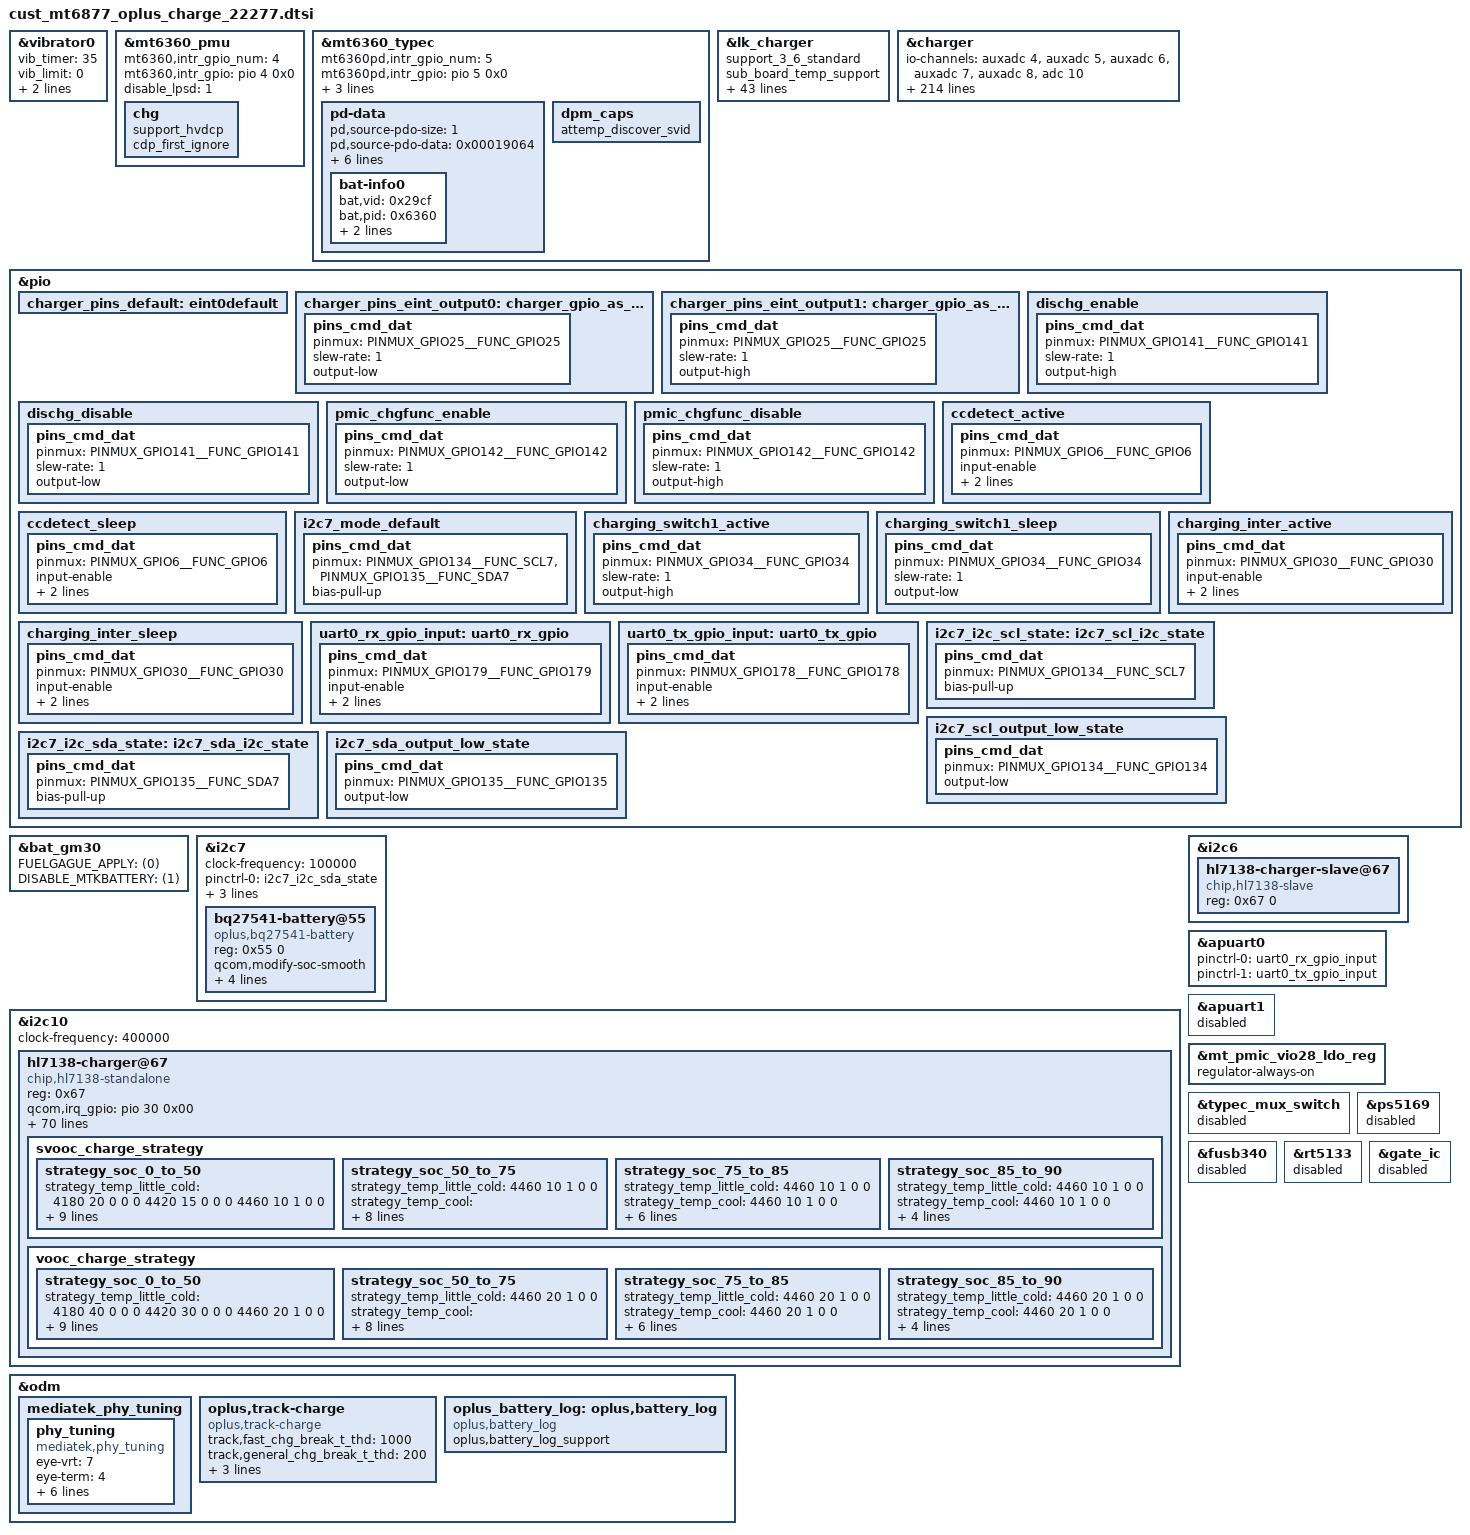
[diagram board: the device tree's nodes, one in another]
// SPDX-License-Identifier: GPL-2.0-only
/*
* Copyright (C) 2020-2021 Oplus. All rights reserved.
*/

//#ifdef OPLUS_FEATURE_CHG_BASIC
/*
 *
 * CPU:				--> MT6877
 * GPIO:
 * AP_AW			--> GPIO117(20181 EVT+20355 T0 NC)
 * LRA_RST			--> GPIO118(20181 EVT+20355 T0 I2S1_BCLK_SMPA)
 * AW_INT			--> GPIO3(20181 EVT+20355 T0 NC)
 * NDT_AW_SCL			--> GPIO147(SCL9)
 * NDT_AW_SDA			--> GPIO148(SDA9)
 *
 * MT6360_CHG_EN		--> GPIO111
 * PERIEN_CHG_ENB		--> GPIO142
 * MT6360_SCL			--> GPIO132(SCL5)
 * MT6360_SDA			--> GPIO133(SDA5)
 * EINT_SUBPMIC_IRQB		--> GPIO4
 * EINT_SUBPMIC_PD_IRQB		--> GPIO5
 *
 * GAUGE_SCL			--> GPIO134(SCL7)
 * GAUGE_SDA			--> GPIO135(SDA7)
 * AP_CLK			--> GPIO180
 * AP_DATA			--> GPIO181
 * SW_CTRL			--> GPIO24
 * USB_ON			--> GPIO25(20181 EVB-GPIO26 PU)
 * MCU_EN			--> GPIO33
 * ASIC_ID			--> GPIO34
 * ASIC_INT			--> GPIO9
 * SHIP_MODE_ON			--> GPIO108
 * UTXD0			--> GPIO178
 * URXD0			--> GPIO179
 *
 * MP2762_DA9313_SCL		--> GPIO191(SCL10)
 * MP2762_DA9313_SDA		--> GPIO192(SDA10)
 * MPS_OTG_EN			--> GPIO107
 * INPUT_PG			--> GPIO29
 * ChargerPump_ID		--> GPIO30
 * MAX77932_IRQB		--> GPIO10
 *
 * USB_ACC_INT			--> GPIO6
 * VBUS_SHORT			--> GPIO167(VIO28)
 *
 * AUXADC:
 * 0				--> AUX_IN0_NTC_AP
 * 1				--> AUX_IN1_NTC_PA1
 * 2				--> AUX_IN2_NTC_PA2
 * 3				--> CAM_FLASH_THER
 * 4				--> AUX_IN4_NTC_USB
 * 5				--> AUX_IN5_NTC_USB
 * 6				--> CHG_MOS_THERM
 * 7				--> MAIN_BOARD_ID
 * 8				--> SUB_BOARD_ID
 *******************************************
 * main pmic:			--> MT6365
 * charge pmic:			--> MT6360
 * charge ic:			--> MP2762GV
 * asic ic:
 * PD				--> SY6610(USE)
 * HZ				--> RT5125
 * PU				--> RK826
 * charge pump ic:
 * PD				--> DA9313/SD77313
 * PU				--> MAX77932/MAX77938
 * haptic ic:			--> AW8697/TFA9873
 * gauge ic:			--> sn28z719/SH366003
 * linear motor:		--> DM-LM0832-67
 */

&vibrator0 {
	vib_timer = <35>;
	vib_limit = <0>;
	vib_vol= <11>;
	lk_vib_vol  = <11>;
	status = "okay";
};

&mt6360_pmu {
	mt6360,intr_gpio_num = <4>; /* direct defined GPIO num */
	mt6360,intr_gpio = <&pio 4 0x0>;
	disable_lpsd = <1>;

	chg {
		support_hvdcp;
		cdp_first_ignore;
	};
};

&mt6360_typec {
	mt6360pd,intr_gpio_num = <5>; /* direct defined GPIO num */
	mt6360pd,intr_gpio = <&pio 5 0x0>;
	mt-tcpc,role_def = <1>; /* 0: Unknown, 1: SNK only, 2: SRC only, 3: DRP, 4: Try.SRC, 5: Try.SNK */
	mt-tcpc,rp_level = <0>; /* 0: Default, 1: 1.5, 2: 3.0 */
	mt-tcpc,vconn_supply  = <1>; /* 0: Never, 1: Always, 2: EMarkOnly, 3: StartOnly */
	pd-data {
		pd,source-pdo-size = <1>;
		pd,source-pdo-data = <0x00019064>; /* Fixed5V1A */

		pd,sink-pdo-size = <3>;
		pd,sink-pdo-data = <0x00019064 0x000190c8 0x0001912c>; /* Fixed5V1A Fixed5V2A Fixed5V3A */

		pd,id-vdo-size = <3>;
		pd,id-vdo-data = <0xd10029cf 0x0 0x63600000>; /* No DP, host + device */

		bat,nr = <1>;
		bat-info0 {
			bat,vid = <0x29cf>;
			bat,pid = <0x6360>;
			bat,mfrs = "bat1";
			bat,design_cap = <16>; /*7.74V*2.15Ah=16.254Wh*/
		};
	};

	dpm_caps {
		attemp_discover_svid;
	};
};

&lk_charger{
	support_3_6_standard;
	sub_board_temp_support;
	sub_board_temp_ts_adc_support;
	sub_board_pull_up_r = <6800>;
	single_batt_external_gauge_support;
	support_external_gauge_battery_encryption;
	support_tuv_authentication;
	support_sdp_screenoff;
	led_brightness = <102>;
	max_charger_voltage = <15000000>;
	boot_battery_voltage = <3400000>;
	usb_charger_current = <500000>;
	ac_charger_current = <2050000>;
	ac_charger_input_current = <1500000>;
	non_std_ac_charger_current = <750000>;
	charging_host_charger_current = <1500000>;
	ta_ac_charger_current = <1500000>;
	pd_charger_current = <500000>;
	support_new_charger_stander;
	precharge_1_step_current = <350>;

	cold_bat_decidegc = <10>;  /*-10C~0C*/
	dcp_temp_cold_fastchg_current = <300>;
	usb_temp_cold_fastchg_current = <300>;
	cdp_temp_cold_fastchg_current = <300>;

	little_cold_bat_decidegc = <0>;    /*0C~5C*/
	dcp_temp_little_cold_fastchg_current = <800>;
	usb_temp_little_cold_fastchg_current = <500>;
	cdp_temp_little_cold_fastchg_current = <800>;

	cool_bat_decidegc = <5>;  /*5C~12C*/
	dcp_temp_cool_fastchg_current = <1600>;
	usb_temp_cool_fastchg_current = <600>;
	cdp_temp_cool_fastchg_current = <1600>;

	little_cool_bat_decidegc = <12>;  /*12C~16C*/
	dcp_temp_little_cool_fastchg_current = <2200>;
	usb_temp_little_cool_fastchg_current = <600>;
	cdp_temp_little_cool_fastchg_current = <1600>;

	normal_bat_decidegc = <16>;       /*16C~45C*/
	dcp_temp_normal_fastchg_current = <2200>;
	usb_temp_normal_fastchg_current = <600>;
	cdp_temp_normal_fastchg_current = <2200>;

	warm_bat_decidegc = <45>;    /*45C~53C*/
	dcp_temp_warm_fastchg_current = <1200>;
	usb_temp_warm_fastchg_current = <600>;
	cdp_temp_warm_fastchg_current = <1200>;

	hot_bat_decidegc = <53>;
};

&charger {
	io-channels = <&auxadc 4>,
		<&auxadc 5>,
		<&auxadc 6>,
		<&auxadc 7>,
		<&auxadc 8>,
		<&adc 10>;
	io-channel-names = "auxadc4-usb_temp_v_l",
		"auxadc5-usb_temp_v_r",
		"auxadc3-chargeric_temp",
		"batcon_temp",
		"usbcon_temp",
		"auxadc6-subboard_temp";

	pinctrl-names = "default", "charger_gpio_as_output_low", "charger_gpio_as_output_high",
		"dischg_enable", "dischg_disable", "pmic_chgfunc_enable", "pmic_chgfunc_disable",
		"ccdetect_active","ccdetect_sleep";
	pinctrl-0 = <&charger_pins_default>;
	pinctrl-1 = <&charger_pins_eint_output0>;
	pinctrl-2 = <&charger_pins_eint_output1>;
	pinctrl-3 = <&dischg_enable>;
	pinctrl-4 = <&dischg_disable>;
	pinctrl-5 = <&pmic_chgfunc_enable>;
	pinctrl-6 = <&pmic_chgfunc_disable>;
	pinctrl-7 = <&ccdetect_active>;
	pinctrl-8 = <&ccdetect_sleep>;

	//qcom,hv_flashled_support;
	qcom,voocphy_support = <3>;
	qcom,chargerid_support;
	qcom,support_subboard_ntc;
	qcom,sub_board_pull_up_r = <6800>;
	qcom,smart_charging_screenoff;
	qcom,smart_chg_soh_support;
	oplus,aging_ffc_version = <1>;
	qcom,suport_pd_9v2a;
	qcom,usbtemp_batttemp_gap = <18>;
	qcom,input_current_charger_ma = <2000>;
	qcom,pd_input_current_charger_ma = <1500>;
	qcom,qc_input_current_charger_ma = <1500>;
	qcom,input_current_usb_ma = <500>;

	qcom,input_current_led_ma = <1200>;
	qcom,input_current_led_ma_high = <1200>;
	qcom,input_current_led_ma_warm = <1500>;
	qcom,input_current_led_ma_normal = <2000>;
	qcom,led_warm_bat_decidegc = <350>;
	qcom,led_high_bat_decidegc = <370>;

	qcom,input_current_camera_ma = <1200>;
	qcom,input_current_cdp_ma = <1500>;

	qcom,input_current_vooc_led_ma_high = <1200>;
	qcom,input_current_vooc_led_ma_warm = <1800>;
	qcom,input_current_vooc_led_ma_normal = <3600>;
	qcom,input_current_vooc_ma_normal = <3600>;
	qcom,vooc_temp_bat_normal_decidegc = <350>;
	qcom,input_current_vooc_ma_warm = <3200>;
	qcom,vooc_temp_bat_warm_decidegc = <370>;
	qcom,input_current_vooc_ma_high = <2200>;
	qcom,vooc_temp_bat_hot_decidegc = <440>;

	qcom,charger_current_vooc_ma_normal = <1800>;

	qcom,chg_ctrl_by_calling;
	qcom,input_current_calling_ma = <1500>;

	qcom,overtemp_bat_decidegc = <350>;
	qcom,iterm_disabled = <0>;
	sw_full_count = <25>;
	qcom,iterm_ma = <253>;
	qcom,recharge-mv = <100>;
	qcom,batt_capacity_mah = <5000>;/*typical capacity*/
	//qcom,batt_capacity_mah = <4870>; /*rated capacity*/

	qcom,removed_bat_decidegc = <390>;  /*<-39C*/

	qcom,cold_bat_decidegc = <100>;  /*-10C~0C*/
	qcom,temp_cold_vfloat_mv = <4465>;
	qcom,temp_freeze_fastchg_current_ma_high = <1200>;
	qcom,temp_freeze_fastchg_current_ma_low = <1200>;
	qcom,temp_freeze_fastchg_current_ma = <1200>;
	qcom,temp_cold_fastchg_current_ma = <1200>;

	qcom,little_cold_bat_decidegc = <0>;    /*0C~5C*/
	qcom,temp_little_cold_vfloat_mv = <4465>;
	qcom,temp_little_cold_fastchg_current_ma_high = <2200>;
	qcom,temp_little_cold_fastchg_current_ma_low = <2200>;
	qcom,temp_little_cold_fastchg_current_ma = <2200>;
	qcom,pd_temp_little_cold_fastchg_current_ma_high = <2700>;
	qcom,pd_temp_little_cold_fastchg_current_ma_low = <1800>;
	qcom,qc_temp_little_cold_fastchg_current_ma_high = <2700>;
	qcom,qc_temp_little_cold_fastchg_current_ma_low = <1800>;

	qcom,cool_bat_decidegc = <50>;  /*5C~12C*/
	qcom,temp_cool_vfloat_mv = <4465>;
	qcom,temp_cool_fastchg_current_ma_high = <2200>;
	qcom,temp_cool_fastchg_current_ma_low = <2200>;
	qcom,pd_temp_cool_fastchg_current_ma_high = <3300>;
	qcom,pd_temp_cool_fastchg_current_ma_low = <2700>;
	qcom,qc_temp_cool_fastchg_current_ma_high = <3300>;
	qcom,qc_temp_cool_fastchg_current_ma_low = <2700>;

	qcom,little_cool_bat_decidegc = <120>;  /*12C~16C*/
	qcom,temp_little_cool_vfloat_mv = <4465>;
	qcom,temp_little_cool_fastchg_current_ma = <2200>;
	qcom,pd_temp_little_cool_fastchg_current_ma = <3300>;
	qcom,qc_temp_little_cool_fastchg_current_ma = <3300>;

	qcom,normal_bat_decidegc = <160>;       /*16C~45C*/
	qcom,temp_normal_vfloat_mv = <4465>;
	qcom,temp_normal_fastchg_current_ma = <2200>;
	qcom,pd_temp_normal_fastchg_current_ma = <3300>;
	qcom,qc_temp_normal_fastchg_current_ma = <3300>;

	qcom,warm_bat_decidegc = <450>;         /*45C~53C*/ /*8pin Bat Vooc project need add 3 degree C*/
	qcom,temp_warm_vfloat_mv = <4130>;
	qcom,temp_warm_fastchg_current_ma = <1152>;
	qcom,pd_temp_warm_fastchg_current_ma = <1152>;
	qcom,qc_temp_warm_fastchg_current_ma = <1152>;
	qcom,temp_warm_fastchg_current_ma_led_on = <1000>;

	qcom,hot_bat_decidegc = <530>;  /* > 53C */

	qcom,non_standard_vfloat_mv = <3980>;
	qcom,non_standard_fastchg_current_ma = <512>;

	qcom,short_c_bat_cv_mv = <4330>;
	qcom,short_c_bat_vfloat_mv = <3800>;
	qcom,short_c_bat_fastchg_current_ma = <512>;

	qcom,cold_vfloat_sw_limit = <4415>;
	qcom,little_cold_vfloat_sw_limit = <4415>;
	qcom,cool_vfloat_sw_limit = <4415>;
	qcom,little_cool_vfloat_sw_limit = <4415>;
	qcom,normal_vfloat_sw_limit = <4415>;
	qcom,warm_vfloat_sw_limit = <4080>;
	qcom,non_standard_vfloat_sw_limit = <3930>;
	qcom,short_c_bat_vfloat_sw_limit = <3750>;

	qcom,max_chg_time_sec = <61200>;
	qcom,charger_hv_thr = <10000>;
	qcom,charger_recv_thr = <9800>;
	qcom,charger_lv_thr = <3400>;
	qcom,vbatt_full_thr = <4465>;
	qcom,vbatt_hv_thr = <4600>;

	qcom,vfloat_step_mv = <8>;
	qcom,cold_vfloat_over_sw_limit = <4475>;
	qcom,little_cold_vfloat_over_sw_limit = <4475>;
	qcom,cool_vfloat_over_sw_limit = <4475>;
	qcom,little_cool_vfloat_over_sw_limit = <4475>;
	qcom,normal_vfloat_over_sw_limit = <4475>;
	qcom,warm_vfloat_over_sw_limit = <4140>;
	qcom,non_standard_vfloat_over_sw_limit = <3990>;

	qcom,support_usbtemp_protect_v2;
	qcom,usbtemp_batt_temp_low = <50>;
	qcom,usbtemp_batt_temp_high = <50>;
	qcom,usbtemp_ntc_temp_low = <57>;
	qcom,usbtemp_ntc_temp_high = <69>;
	qcom,usbtemp_temp_gap_low_with_batt_temp = <7>;
	qcom,usbtemp_temp_gap_high_with_batt_temp = <12>;
	qcom,usbtemp_temp_gap_low_without_batt_temp = <12>;
	qcom,usbtemp_temp_gap_high_without_batt_temp = <24>;
	qcom.usbtemp_rise_fast_temp_low = <3>;
	qcom.usbtemp_rise_fast_temp_high = <3>;
	qcom.usbtemp_rise_fast_temp_count_low = <30>;
	qcom.usbtemp_rise_fast_temp_count_high = <20>;

	qcom,usbtemp_cool_down_ntc_low = <54>;
	qcom,usbtemp_cool_down_ntc_high = <65>;
	qcom,usbtemp_cool_down_gap_low = <12>;
	qcom,usbtemp_cool_down_gap_high = <20>;
	qcom,usbtemp_cool_down_recover_ntc_low = <48>;
	qcom,usbtemp_cool_down_recover_ntc_high = <60>;
	qcom,usbtemp_cool_down_recover_gap_low = <6>;
	qcom,usbtemp_cool_down_recover_gap_high = <15>;

	qcom,vbatt_power_off = <3300>;
	qcom,vbatt_soc_1 = <3410>;
	qcom,vooc_project = <13>;
	qcom,vbatt_num = <1>;
	qcom,new_ui_warning_support;
	qcom,ffc_support;
	qcom,dual_ffc;

	qcom,normal_vterm_hw_inc = <18>;
	qcom,non_normal_vterm_hw_inc = <18>;

	qcom,ff1_normal_fastchg_ma = <1500>;
	qcom,ff1_warm_fastchg_ma = <1600>;

	qcom,ffc2_normal_fastchg_ma = <1500>;/*12C~35c*/
	qcom,ffc2_warm_fastchg_ma = <1600>;/*35C~40c*/
	qcom,ffc2_temp_low_decidegc = <120>;
	qcom,ffc2_temp_warm_decidegc = <350>;
	qcom,ffc2_temp_high_decidegc = <400>;

	qcom,ff1_exit_step_ma = <150>;
	qcom,ff1_warm_exit_step_ma = <150>;
	qcom,ffc2_exit_step_ma = <150>;
	qcom,ffc2_warm_exit_step_ma = <150>;

	qcom,ffc_normal_vfloat_sw_limit = <4515>;
	qcom,ffc_temp_normal_vfloat_mv = <4580>;
	qcom,ffc_normal_vfloat_over_sw_limit = <4580>;
	qcom,ffc_warm_vfloat_sw_limit = <4515>;

	qcom,ffc2_normal_vfloat_sw_limit = <4515>;
	qcom,ffc2_temp_normal_vfloat_mv = <4580>;
	qcom,ffc2_normal_vfloat_over_sw_limit = <4580>;
	qcom,ffc2_warm_vfloat_sw_limit = <4515>;

	qcom,default_iterm_ma = <253>;
	qcom,default_temp_normal_fastchg_current_ma = <2200>;
	qcom,default_normal_vfloat_sw_limit = <4415>;
	qcom,default_temp_normal_vfloat_mv = <4465>;
	qcom,default_normal_vfloat_over_sw_limit = <4475>;

	qcom,default_temp_little_cool_fastchg_current_ma = <2200>;
	qcom,default_little_cool_vfloat_sw_limit = <4415>;
	qcom,default_temp_little_cool_vfloat_mv = <4465>;
	qcom,default_little_cool_vfloat_over_sw_limit = <4475>;

	//for smart charge begin
	qcom,smart_chg_bcc_support;
	oplus,boot_reset_adapter;
	/*If use subboard NTC as battery temp, config it as 20, otherwise 0 */
	oplus,tbatt_power_off_cali_temp = <20>;
	oplus,smooth_switch_v2;
	oplus,reserve_chg_soc = <3>;
	oplus,reserve_dis_soc = <3>;
	qcom,ui_soc_decimal_speedmin = <20>;//2A
	qcom,vooc_show_ui_soc_decimal;
	qcom,check_batt_full_by_sw;
	qcom,external_gauge;
	qcom,chg_ctrl_by_lcd;
	qcom,chg_ctrl_by_camera;
	qcom,sw_vfloat_over_protect_enable;
	qcom,support_ntc_01c_precision;
	qcom,support_abnormal_adapter;

	oplus,switch2-ctrl-gpio = <&pio 34 0x00>;
	oplus,uart_tx-gpio = <&pio 178 0x00>;
	oplus,uart_rx-gpio = <&pio 179 0x00>;

	//for PD9V or QC9V
	qcom,vbatt_pdqc_to_5v_thr = <4500>;
	qcom,vbatt_pdqc_to_9v_thr = <4500>;

	qcom,support_3p6_standard;
	//GPIO config:
	qcom,chargerid_switch-gpio = <&pio 25 0x00>;
	qcom,dischg-gpio = <&pio 141 0x00>;
	qcom,ccdetect-gpio = <&pio 6 0x00>;

	qcom,pmic_chgfunc = <&pio 142 0x00>;
};

&pio {
	charger_pins_default: eint0default {
	};

	charger_pins_eint_output0: charger_gpio_as_output_low {
		pins_cmd_dat {
			pinmux = <PINMUX_GPIO25__FUNC_GPIO25>;
			slew-rate = <1>;
			output-low;
		};
	};

	charger_pins_eint_output1: charger_gpio_as_output_high {
		pins_cmd_dat {
			pinmux = <PINMUX_GPIO25__FUNC_GPIO25>;
			slew-rate = <1>;
			output-high;
		};
	};

	dischg_enable: dischg_enable {
		pins_cmd_dat {
			pinmux = <PINMUX_GPIO141__FUNC_GPIO141>;
			slew-rate = <1>;
			output-high;
		};
	};

	dischg_disable: dischg_disable {
		pins_cmd_dat {
			pinmux = <PINMUX_GPIO141__FUNC_GPIO141>;
			slew-rate = <1>;
			output-low;
		};
	};

	pmic_chgfunc_enable: pmic_chgfunc_enable {
		pins_cmd_dat {
			pinmux = <PINMUX_GPIO142__FUNC_GPIO142>;
			slew-rate = <1>;
			output-low;
		};
	};

	pmic_chgfunc_disable: pmic_chgfunc_disable {
		pins_cmd_dat {
			pinmux = <PINMUX_GPIO142__FUNC_GPIO142>;
			slew-rate = <1>;
			output-high;
		};
	};

	ccdetect_active: ccdetect_active {
		pins_cmd_dat {
			pinmux = <PINMUX_GPIO6__FUNC_GPIO6>;
			input-enable;
			slew-rate = <0>;
			bias-disable;
		};
	};

	ccdetect_sleep: ccdetect_sleep {
		pins_cmd_dat {
			pinmux = <PINMUX_GPIO6__FUNC_GPIO6>;
			input-enable;
			slew-rate = <0>;
			bias-disable;
		};
	};
};

&bat_gm30 {
	FUELGAGUE_APPLY = <(0)>;
	DISABLE_MTKBATTERY = <(1)>;
};

&i2c7 {
	status = "okay";
	clock-frequency = <100000>;

	bq27541-battery@55{
		status = "okay";
		compatible = "oplus,bq27541-battery";
		reg = <0x55 0>;
		qcom,modify-soc-smooth;
		qcom,gauge_num = <0>;
		qcom,sha1_key_index = <2>;
		oplus,enable_sleep_mode;
		pinctrl-names = "default";
		pinctrl-0 = <&i2c7_mode_default>;
		//qcom,bq28z610_need_balancing;
	};
};

&pio {
	i2c7_mode_default: i2c7_mode_default {
		pins_cmd_dat {
			pinmux = <PINMUX_GPIO134__FUNC_SCL7>,
				<PINMUX_GPIO135__FUNC_SDA7>;
			bias-pull-up;
		};
	};
};

&i2c10 {
	status = "okay";
	clock-frequency = <400000>;//400K
	hl7138-charger@67{
		status = "okay";
		compatible = "chip,hl7138-standalone";
		reg = <0x67>;

		qcom,irq_gpio = <&pio 30 0x00>;
		interrupt-parent = <&pio>;
		interrupts = <30 0>;

		pinctrl-names = "switch1_act_switch2_act", "switch1_sleep_switch2_sleep",
				"charging_inter_active", "charging_inter_sleep";
		pinctrl-0 = <&charging_switch1_active>;
		pinctrl-1 = <&charging_switch1_sleep>;
		pinctrl-2 = <&charging_inter_active>;
		pinctrl-3 = <&charging_inter_sleep>;

		qcom,external_gauge_support;
		qcom,charging_switch1-gpio = <&pio 34 0x00>;

		qcom,voocphy_dual_cp_support;
		qcom,copycat_vooc_support;
		qcom,slave_cp_enable_thr = <1900>;		//2000-100mA
		qcom,slave_cp_disable_thr_high = <1600>;	//1500+100mA
		qcom,voocphy_current_default = <61>;

		qcom,svooc_cool_down_current_limit = <122 20 20 24 30 34 40 44 50 54 60 64 70 74>;
		qcom,vooc_cool_down_current_limit = <61 20 20 24 30 34 40 44 50 54 60 64 70 74>;

		qcom,abnormal_adapter_current = <122 122 100 100 80 80 60 60 40 40>;
		qcom,vooc_little_cold_full_voltage = <4460>;
		qcom,vooc_cool_full_voltage = <4460>;
		qcom,vooc_warm_full_voltage = <4130>;
		qcom,vooc_1time_full_voltage = <4530>;
		qcom,vooc_ntime_full_voltage = <4520>;
		qcom,low_curr_full_t1 = <120>;
		qcom,low_curr_full_t2 = <350>;
		qcom,low_curr_full_t3 = <430>;
		qcom,range1_low_curr_full = <1450 4520
						1350 4515
						1250 4500
						1150 4490
						1050 4480>;
		qcom,range2_low_curr_full = <1650 4520
						1550 4515
						1450 4500
						1350 4490
						1250 4480>;

		qcom,vooc_multistep_initial_batt_temp = <1000>;
		qcom,vooc_little_cool_temp = <160>;
		qcom,vooc_cool_temp = <120>;
		qcom,vooc_little_cold_temp = <50>;
		qcom,vooc_normal_low_temp = <350>;
		qcom,vooc_strategy_normal_current = <122>; //12.2A
		qcom,vooc_normal_to_little_cool_current = <100>;
		qcom,vooc_batt_over_high_temp = <510>;
		qcom,vooc-low-temp = <0>;
		qcom,vooc-high-temp = <500>;
		qcom,vooc-low-soc = <0>;
		qcom,vooc-high-soc = <90>;
		qcom,vooc-normal-high-temp = <440>;
		qcom,vooc-warm-allow-vol = <4000>;
		qcom,vooc-warm-allow-soc = <50>;

		qcom,vooc_strategy1_batt_high_temp0 = <385>;
		qcom,vooc_strategy1_batt_high_temp1 = <395>;
		qcom,vooc_strategy1_batt_high_temp2 = <420>;
		qcom,vooc_strategy1_batt_low_temp2 = <410>;
		qcom,vooc_strategy1_batt_low_temp1 = <385>;
		qcom,vooc_strategy1_batt_low_temp0 = <375>;

		qcom,vooc_strategy1_high_current0 = <80>;
		qcom,vooc_strategy1_high_current1 = <60>;
		qcom,vooc_strategy1_high_current2 = <40>;
		qcom,vooc_strategy1_low_current2 = <60>;
		qcom,vooc_strategy1_low_current1 = <80>;
		qcom,vooc_strategy1_low_current0 = <122>;

		qcom,voocphy_ibat_over_current = <13500>;
		qcom,voocphy_svooc_cp_max_ibus = <3500>;
		qcom,voocphy_vooc_cp_max_ibus = <3500>;
		qcom,voocphy_cp_max_ibus = <3500>;

		qcom,voocphy_freq_mincore = <1053000>;
		qcom,voocphy_freq_midcore = <1540000>;
		qcom,voocphy_freq_maxcore = <1540000>;
		qcom,voocphy_current_change_timeout = <100>;

		svooc_batt_sys_curve = <0 1 0 1 0 0 0	// 4000mA
					1 1 1 1 0 0 0	// 4604mV
					0 0 1 1 0 1 0	// 2600mA
					1 1 1 1 0 0 0	// 4604mV
					0 0 0 1 0 1 1	// 1100mA
					1 1 1 1 0 0 0>;	// 4604mV

		vooc_batt_sys_curve =  <0 1 0 1 0 0 0	// 4000mA
					1 1 1 1 0 0 0	// 4604mV
					0 0 1 1 0 1 0	// 2600mA
					1 1 1 1 0 0 0	// 4604mV
					0 0 0 1 0 1 1	// 1100mA
					1 1 1 1 0 0 0>;	// 4604mV

		svooc_charge_strategy {
			strategy_soc_0_to_50 {
				strategy_temp_little_cold = <4180 20 0 0 0
								 4420 15 0 0 0
								 4460 10 1 0 0>;
				strategy_temp_cool =        <4180 24 0 0 0
								 4450 15 0 0 0
								 4460 10 1 0 0>;
				strategy_temp_little_cool = <4180 40 0 0 0
								 4480 30 0 0 0
								 4480 25 0 0 0
								 4514 20 0 0 0
								 4514 15 0 0 0
								 4520 10 1 0 0>;
				strategy_temp_normal_low =  <4200 61 0 100 0
								 4200 50 0 360 0
								 4350 40 0 1200 0
								 4480 30 0 0 0
								 4480 25 0 0 0
								 4514 20 0 0 0
								 4514 15 0 0 0
								 4520 10 1 0 0>;
				strategy_temp_normal_high = <4200 61 0 100 0
								 4200 50 0 360 0
								 4350 40 0 1200 0
								 4480 30 0 0 0
								 4480 25 0 0 0
								 4514 20 0 0 0
								 4514 15 0 0 0
								 4520 10 1 0 0>;
				strategy_temp_warm =        <4130 10 1 0 0>;
			};

			strategy_soc_50_to_75 {
				strategy_temp_little_cold = <4460 10 1 0 0>;
				strategy_temp_cool =        <4450 15 0 0 0
								 4460 10 1 0 0>;
				strategy_temp_little_cool = <4514 20 0 0 0
								 4514 15 0 0 0
								 4520 10 1 0 0>;
				strategy_temp_normal_low =  <4480 30 0 0 0
								 4480 25 0 0 0
								 4514 20 0 0 0
								 4514 15 0 0 0
								 4520 10 1 0 0>;
				strategy_temp_normal_high =  <4480 25 0 0 0
								 4514 20 0 0 0
								 4514 15 0 0 0
								 4520 10 1 0 0>;
				strategy_temp_warm =         <4130 10 1 0 0>;
			};

			strategy_soc_75_to_85 {
				strategy_temp_little_cold =  <4460 10 1 0 0>;
				strategy_temp_cool =         <4460 10 1 0 0>;
				strategy_temp_little_cool =  <4520 10 1 0 0>;
				strategy_temp_normal_low =   <4514 15 0 0 0
								 4520 10 1 0 0>;
				strategy_temp_normal_high =  <4514 15 0 0 0
								 4520 10 1 0 0>;
				strategy_temp_warm =         <4130 10 1 0 0>;
			};

			strategy_soc_85_to_90 {
				strategy_temp_little_cold =  <4460 10 1 0 0>;
				strategy_temp_cool =         <4460 10 1 0 0>;
				strategy_temp_little_cool =  <4520 10 1 0 0>;
				strategy_temp_normal_low =   <4520 10 1 0 0>;
				strategy_temp_normal_high =  <4520 10 1 0 0>;
				strategy_temp_warm =         <4130 10 1 0 0>;
			};
		};

		vooc_charge_strategy {
			strategy_soc_0_to_50 {
				strategy_temp_little_cold =  <4180 40 0 0 0
								 4420 30 0 0 0
								 4460 20 1 0 0>;
				strategy_temp_cool =         <4180 40 0 0 0
								 4450 30 0 0 0
								 4460 20 1 0 0>;
				strategy_temp_little_cool =  <4480 60 0 0 0
								 4480 50 0 0 0
								 4514 40 0 0 0
								 4514 30 0 0 0
								 4520 20 1 0 0>;
				strategy_temp_normal_low =   <4480 60 0 0 0
								 4480 50 0 0 0
								 4514 40 0 0 0
								 4514 30 0 0 0
								 4520 20 1 0 0>;
				strategy_temp_normal_high =   <4480 60 0 0 0
								 4480 50 0 0 0
								 4514 40 0 0 0
								 4514 30 0 0 0
								 4520 20 1 0 0>;
				strategy_temp_warm =          <4130 20 1 0 0>;
			};

			strategy_soc_50_to_75 {
				strategy_temp_little_cold =   <4460 20 1 0 0>;
				strategy_temp_cool =          <4450 30 0 0 0
								 4460 20 1 0 0>;
				strategy_temp_little_cool =   <4514 40 0 0 0
								 4514 30 0 0 0
								 4520 20 1 0 0>;
				strategy_temp_normal_low =    <4480 60 0 0 0
								 4480 50 0 0 0
								 4514 40 0 0 0
								 4514 30 0 0 0
								 4520 20 1 0 0>;
				strategy_temp_normal_high =   <4480 50 0 0 0
								 4514 40 0 0 0
								 4514 30 0 0 0
								 4520 20 1 0 0>;
				strategy_temp_warm =          <4130 20 1 0 0>;
			};

			strategy_soc_75_to_85 {
				strategy_temp_little_cold =   <4460 20 1 0 0>;
				strategy_temp_cool =          <4460 20 1 0 0>;
				strategy_temp_little_cool =   <4520 20 1 0 0>;
				strategy_temp_normal_low =    <4514 30 0 0 0
								 4520 20 1 0 0>;
				strategy_temp_normal_high =   <4514 30 0 0 0
								 4520 20 1 0 0>;
				strategy_temp_warm =          <4130 20 1 0 0>;
			};

			strategy_soc_85_to_90 {
				strategy_temp_little_cold =   <4460 20 1 0 0>;
				strategy_temp_cool =          <4460 20 1 0 0>;
				strategy_temp_little_cool =   <4520 20 1 0 0>;
				strategy_temp_normal_low =    <4520 20 1 0 0>;
				strategy_temp_normal_high =   <4520 20 1 0 0>;
				strategy_temp_warm =          <4130 20 1 0 0>;
			};
		};
	};
};

&i2c6 {
	status = "okay";
	hl7138-charger-slave@67{
		status = "okay";
		compatible = "chip,hl7138-slave";
		reg = <0x67 0>;
	};
};

&pio {
	charging_switch1_active: charging_switch1_active {
		pins_cmd_dat {
			pinmux = <PINMUX_GPIO34__FUNC_GPIO34>;
			slew-rate = <1>;
			output-high;
		};
	};

	charging_switch1_sleep: charging_switch1_sleep {
		pins_cmd_dat {
			pinmux = <PINMUX_GPIO34__FUNC_GPIO34>;
			slew-rate = <1>;
			output-low;
		};
	};

	charging_inter_active: charging_inter_active {
		pins_cmd_dat {
			pinmux = <PINMUX_GPIO30__FUNC_GPIO30>;
			input-enable;
			slew-rate = <0>;
			bias-disable;
		};
	};

	charging_inter_sleep: charging_inter_sleep {
		pins_cmd_dat {
			pinmux = <PINMUX_GPIO30__FUNC_GPIO30>;
			input-enable;
			slew-rate = <0>;
			bias-disable;
		};
	};
};

&apuart0 {
	pinctrl-names = "uart0_rx_gpio",
			"uart0_tx_gpio";
	pinctrl-0 = <&uart0_rx_gpio_input>;
	pinctrl-1 = <&uart0_tx_gpio_input>;
	status = "okay";
};

&apuart1 {
	status = "disabled";
};

&pio {
	uart0_rx_gpio_input:uart0_rx_gpio {
		pins_cmd_dat {
			pinmux = <PINMUX_GPIO179__FUNC_GPIO179>;
			input-enable;
			slew-rate = <0>;
			bias-disable;
		};
	};

	uart0_tx_gpio_input:uart0_tx_gpio {
		pins_cmd_dat {
			pinmux = <PINMUX_GPIO178__FUNC_GPIO178>;
			input-enable;
			slew-rate = <0>;
			bias-disable;
		};
	};
};

&mt_pmic_vio28_ldo_reg {
	regulator-always-on;//for VBUS_SHORT
};

&typec_mux_switch {
	status = "disabled";
};

&ps5169{
	status = "disabled";
};

&fusb340 {
	status = "disabled";
};

&odm {
	mediatek_phy_tuning: mediatek_phy_tuning {
		phy_tuning {
			compatible = "mediatek,phy_tuning";
			eye-vrt = <7>;
			eye-term = <4>;
			eye-rev6 = <3>;
			u2_discth = <0xc>;
			host-eye-vrt = <6>;
			host-eye-term = <6>;
			host-eye-rev6 = <3>;
			host_u2_discth = <0xc>;
		};
	};

	oplus,track-charge {
		compatible = "oplus,track-charge";
		track,fast_chg_break_t_thd = <1000>;
		track,general_chg_break_t_thd = <200>;
		track,voocphy_type = <3>;
		track,wired_max_power = <67000>;
		track,wired_fast_chg_scheme = <2>;
	};

	oplus_battery_log: oplus,battery_log {
		compatible = "oplus,battery_log";
		oplus,battery_log_support;
	};
};

&i2c7 {
	pinctrl-names = "i2c-state", "output-low-state", "i2c-state-1", "output-low-state-1";
	pinctrl-0 = <&i2c7_i2c_sda_state>;
	pinctrl-1 = <&i2c7_sda_output_low_state>;
	pinctrl-2 = <&i2c7_i2c_scl_state>;
	pinctrl-3 = <&i2c7_scl_output_low_state>;
};

&pio {
	i2c7_i2c_scl_state: i2c7_scl_i2c_state {
		pins_cmd_dat {
			pinmux = <PINMUX_GPIO134__FUNC_SCL7>;
			bias-pull-up;
		};
	};
	i2c7_scl_output_low_state: i2c7_scl_output_low_state {
		pins_cmd_dat {
			pinmux = <PINMUX_GPIO134__FUNC_GPIO134>;
			output-low;
		};
	};

	i2c7_i2c_sda_state: i2c7_sda_i2c_state {
		pins_cmd_dat {
			pinmux = <PINMUX_GPIO135__FUNC_SDA7>;
			bias-pull-up;
		};
	};
	i2c7_sda_output_low_state: i2c7_sda_output_low_state {
		pins_cmd_dat {
			pinmux = <PINMUX_GPIO135__FUNC_GPIO135>;
			output-low;
		};
	};
};

&rt5133 {
	status = "disabled";
};

&gate_ic {
	status = "disabled";
};

//#endif /*OPLUS_FEATURE_CHG_BASIC*/
